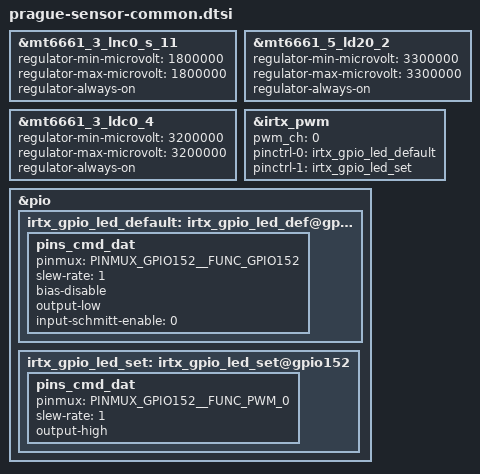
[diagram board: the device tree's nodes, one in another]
/* aw963x power start */
&mt6661_3_lnc0_s_11 {
	regulator-min-microvolt = <1800000>;
	regulator-max-microvolt = <1800000>;
	regulator-always-on;
};

/* 9373 power end */
/* psensor power start */
&mt6661_5_ld20_2 {
	regulator-min-microvolt = <3300000>;
	regulator-max-microvolt = <3300000>;
	regulator-always-on;
};
/* psensor power end */

&mt6661_3_ldc0_4 {
	regulator-min-microvolt = <3200000>;
	regulator-max-microvolt = <3200000>;
	regulator-always-on;
};

/* GPIO IRTX start */
&irtx_pwm {
	pwm_ch = <0>;
	pinctrl-names = "irtx_gpio_led_default", "irtx_gpio_led_set";
	pinctrl-0 = <&irtx_gpio_led_default>;
	pinctrl-1 = <&irtx_gpio_led_set>;
	status = "okay";
};

&pio {
	/* IRTX GPIO Settings -Start */
	/* default: GPIO0, output, high */
	irtx_gpio_led_default:irtx_gpio_led_def@gpio152 {
		pins_cmd_dat {
			pinmux = <PINMUX_GPIO152__FUNC_GPIO152>;
			slew-rate = <1>;
			bias-disable;
			output-low;
			input-schmitt-enable = <0>;
		};
	};
	irtx_gpio_led_set:irtx_gpio_led_set@gpio152 {
		pins_cmd_dat {
			pinmux = <PINMUX_GPIO152__FUNC_PWM_0>;
			slew-rate = <1>;
			output-high;
		};
	};
};
/* GPIO IRTX end */
